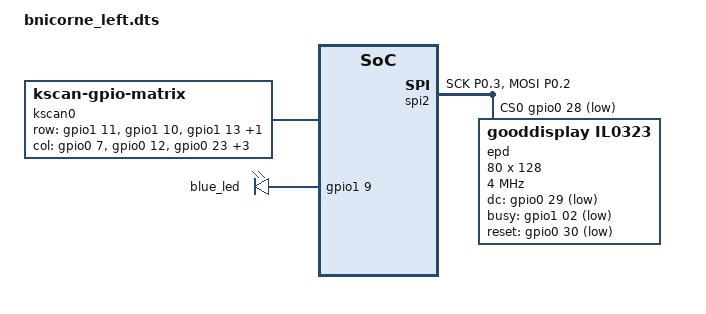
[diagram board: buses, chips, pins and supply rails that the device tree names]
/*
*
* Copyright (c) 2024 Kyle Brown
* SPDX-License-Identifier: MIT
*
*/

#include "bnicorne.dtsi"

/{
    chosen {
        zephyr,display = &epd;
    };

    kscan0: kscan {
        compatible = "zmk,kscan-gpio-matrix";
        wakeup-source;

        diode-direction = "col2row";
        row-gpios
            = <&gpio1 11 (GPIO_ACTIVE_HIGH | GPIO_PULL_DOWN)>
            , <&gpio1 10 (GPIO_ACTIVE_HIGH | GPIO_PULL_DOWN)>
            , <&gpio1 13 (GPIO_ACTIVE_HIGH | GPIO_PULL_DOWN)>
            , <&gpio1 15 (GPIO_ACTIVE_HIGH | GPIO_PULL_DOWN)>
            ;

        col-gpios
            = <&gpio0  7 GPIO_ACTIVE_HIGH>
            , <&gpio0 12 GPIO_ACTIVE_HIGH>
            , <&gpio0 23 GPIO_ACTIVE_HIGH>
            , <&gpio0 21 GPIO_ACTIVE_HIGH>
            , <&gpio0 19 GPIO_ACTIVE_HIGH>
            , <&gpio0 22 GPIO_ACTIVE_HIGH>
            ;
    };

    leds {
        compatible = "gpio-leds";
        blue_led: led_0 {
            gpios = <&gpio1 9 GPIO_ACTIVE_HIGH>;
        };
    };
};

&pinctrl {
    spi2_default: spi2_default {
        group1 {
            psels = <NRF_PSEL(SPIM_SCK, 0, 3)>,
                <NRF_PSEL(SPIM_MOSI, 0, 2)>;
        };
    };


    spi2_sleep: spi2_sleep {
        group1 {
            psels = <NRF_PSEL(SPIM_SCK, 0, 3)>,
                <NRF_PSEL(SPIM_MOSI, 0, 2)>;
            low-power-enable;
        };
    };


};


&spi2 {
    status = "okay";
    compatible = "nordic,nrf-spim";
    pinctrl-0 = <&spi2_default>;
    pinctrl-1 = <&spi2_sleep>;
    pinctrl-names = "default", "sleep";
    cs-gpios = <&gpio0 28 GPIO_ACTIVE_LOW>;

    epd: il0323@0 {
        compatible = "gooddisplay,il0323";
        reg =  <0>;
        width = <80>;
        height = <128>;
        spi-max-frequency = <4000000>;
        dc-gpios = <&gpio0 29 GPIO_ACTIVE_LOW>;
        busy-gpios = <&gpio1 02 GPIO_ACTIVE_LOW>;
        reset-gpios = <&gpio0 30 GPIO_ACTIVE_LOW>;
        pwr = [03 00 26 26];
        cdi = <0xd2>;
        tcon = <0x22>;
    };
};
